# STM32H742AGI6 register map
File version: 1.0
Registers are 32-bit, access not given, reset 0x0 unless marked. A register's access mark holds for its fields unless they carry their own. Offsets are from the block's base; [hi:lo] are bit positions; {n}, {i} and the like mark numbered series; 'fields as' and 'values as' point back to an identical list.

## DMA2D
Base 0x52001000
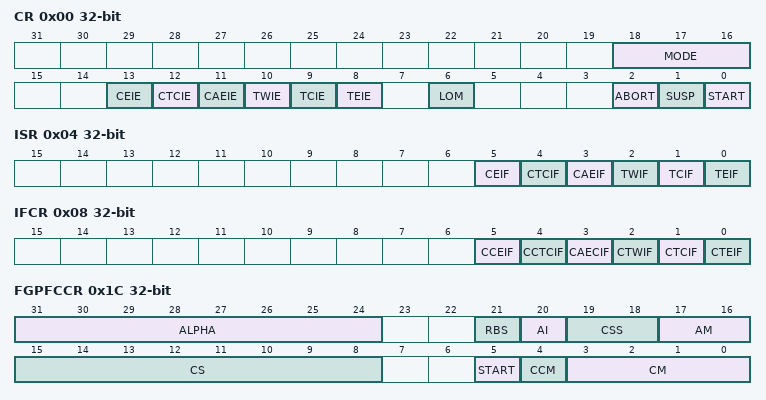
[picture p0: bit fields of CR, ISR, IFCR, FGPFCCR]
0x00 CR
  [18:16] MODE, [13] CEIE, [12] CTCIE, [11] CAEIE, [10] TWIE, [9] TCIE, [8] TEIE, [6] LOM, [2] ABORT, [1] SUSP, [0] START
0x04 ISR
  [5] CEIF, [4] CTCIF, [3] CAEIF, [2] TWIF, [1] TCIF, [0] TEIF
0x08 IFCR
  [5] CCEIF, [4] CCTCIF, [3] CAECIF, [2] CTWIF, [1] CTCIF, [0] CTEIF
0x0C FGMAR
  [31:0] MA
0x10 FGOR
  [15:0] LO
0x14 BGMAR
  [31:0] MA
0x18 BGOR
  [15:0] LO
0x1C FGPFCCR
  [31:24] ALPHA, [21] RBS, [20] AI, [19:18] CSS, [17:16] AM, [15:8] CS, [5] START, [4] CCM, [3:0] CM
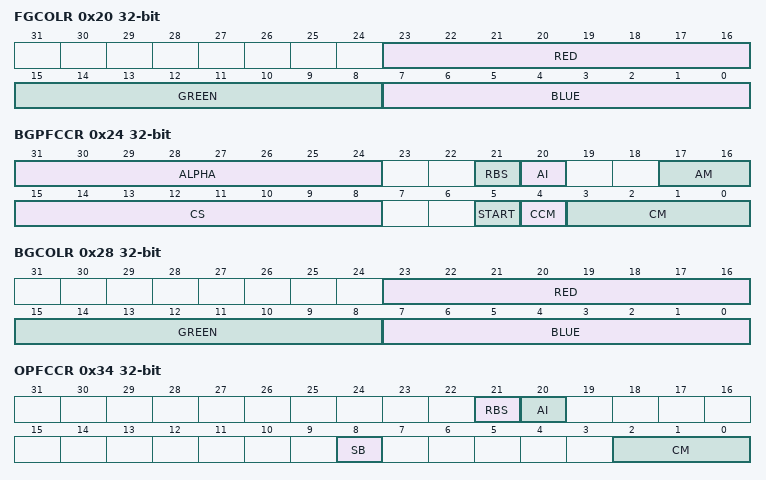
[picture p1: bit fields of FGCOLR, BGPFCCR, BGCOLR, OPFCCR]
0x20 FGCOLR
  [23:16] RED, [15:8] GREEN, [7:0] BLUE
0x24 BGPFCCR
  [31:24] ALPHA, [21] RBS, [20] AI, [17:16] AM, [15:8] CS, [5] START, [4] CCM, [3:0] CM
0x28 BGCOLR
  [23:16] RED, [15:8] GREEN, [7:0] BLUE
0x2C FGCMAR
  [31:0] MA
0x30 BGCMAR
  [31:0] MA
0x34 OPFCCR
  [21] RBS, [20] AI, [8] SB, [2:0] CM
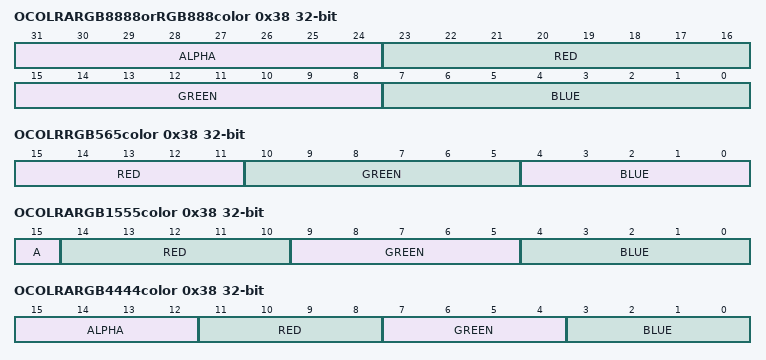
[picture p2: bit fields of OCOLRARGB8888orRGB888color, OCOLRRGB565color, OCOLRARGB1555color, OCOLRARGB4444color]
0x38 OCOLRARGB8888orRGB888color
  [31:24] ALPHA, [23:16] RED, [15:8] GREEN, [7:0] BLUE
0x38 OCOLRRGB565color
  [15:11] RED, [10:5] GREEN, [4:0] BLUE
0x38 OCOLRARGB1555color
  [15] A, [14:10] RED, [9:5] GREEN, [4:0] BLUE
0x38 OCOLRARGB4444color
  [15:12] ALPHA, [11:8] RED, [7:4] GREEN, [3:0] BLUE
0x3C OMAR
  [31:0] MA
0x40 OOR
  [15:0] LO
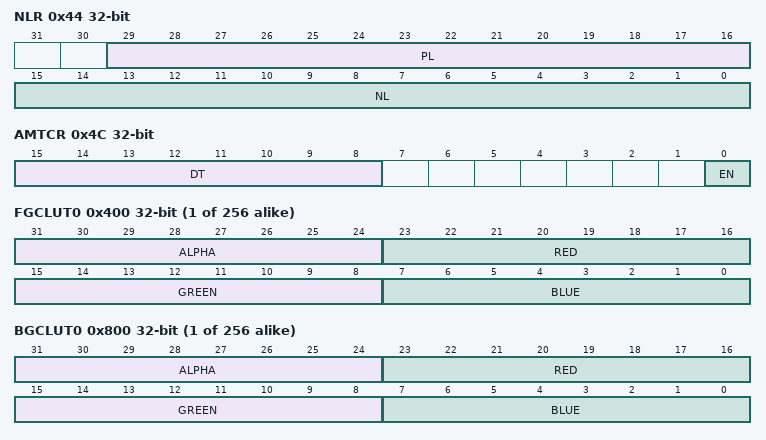
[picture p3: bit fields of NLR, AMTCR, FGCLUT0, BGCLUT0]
0x44 NLR
  [29:16] PL, [15:0] NL
0x48 LWR
  [15:0] LW
0x4C AMTCR
  [15:8] DT, [0] EN
{0x400+4i} FGCLUT{i} (i=0..255)
  [31:24] ALPHA, [23:16] RED, [15:8] GREEN, [7:0] BLUE
{0x800+4i} BGCLUT{i} (i=0..255)
  [31:24] ALPHA, [23:16] RED, [15:8] GREEN, [7:0] BLUE

## FLASH
Base 0x52002000
0x04 KEYR1
  [31:0] KEY1R
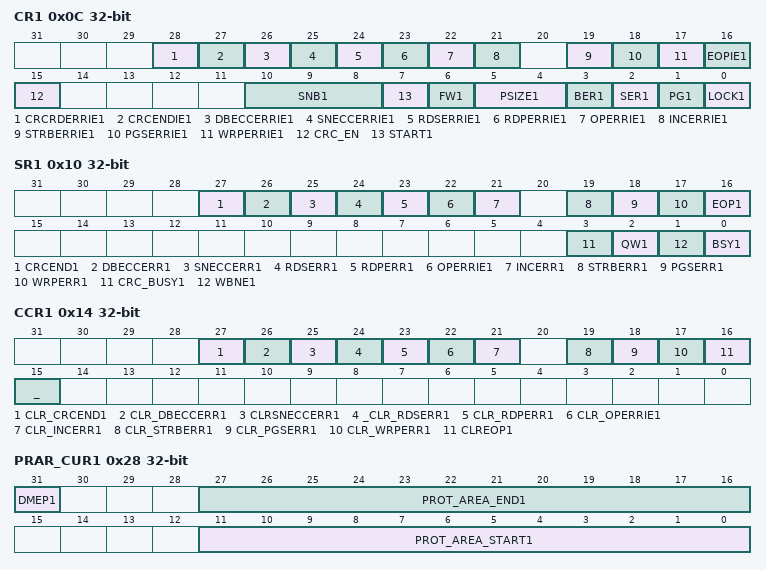
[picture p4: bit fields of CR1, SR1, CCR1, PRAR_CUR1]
0x0C CR1
  [28] CRCRDERRIE1, [27] CRCENDIE1, [26] DBECCERRIE1, [25] SNECCERRIE1, [24] RDSERRIE1, [23] RDPERRIE1, [22] OPERRIE1, [21] INCERRIE1, [19] STRBERRIE1, [18] PGSERRIE1, [17] WRPERRIE1, [16] EOPIE1, [15] CRC_EN, [10:8] SNB1, [7] START1, [6] FW1, [5:4] PSIZE1, [3] BER1, [2] SER1, [1] PG1, [0] LOCK1
0x10 SR1
  [27] CRCEND1, [26] DBECCERR1, [25] SNECCERR1, [24] RDSERR1, [23] RDPERR1, [22] OPERRIE1, [21] INCERR1, [19] STRBERR1, [18] PGSERR1, [17] WRPERR1, [16] EOP1, [3] CRC_BUSY1, [2] QW1, [1] WBNE1, [0] BSY1
0x14 CCR1
  [27] CLR_CRCEND1, [26] CLR_DBECCERR1, [25] CLRSNECCERR1, [24] _CLR_RDSERR1, [23] CLR_RDPERR1, [22] CLR_OPERRIE1, [21] CLR_INCERR1, [19] CLR_STRBERR1, [18] CLR_PGSERR1, [17] CLR_WRPERR1, [16] CLREOP1, [15] _
0x28 PRAR_CUR1
  [31] DMEP1, [27:16] PROT_AREA_END1, [11:0] PROT_AREA_START1
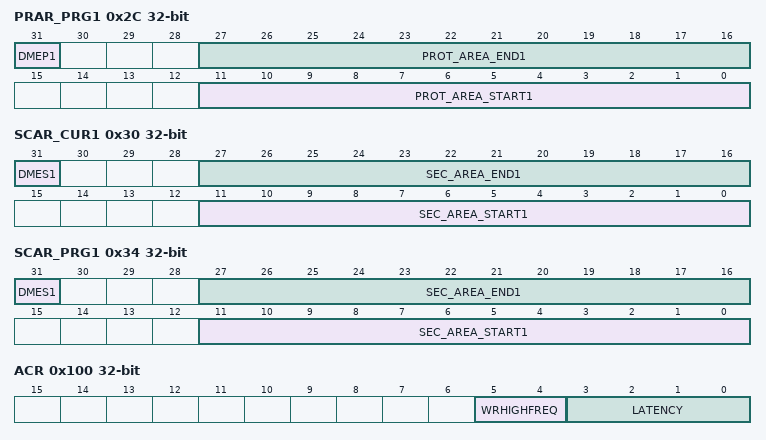
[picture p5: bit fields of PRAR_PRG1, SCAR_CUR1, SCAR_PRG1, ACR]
0x2C PRAR_PRG1
  [31] DMEP1, [27:16] PROT_AREA_END1, [11:0] PROT_AREA_START1
0x30 SCAR_CUR1
  [31] DMES1, [27:16] SEC_AREA_END1, [11:0] SEC_AREA_START1
0x34 SCAR_PRG1
  [31] DMES1, [27:16] SEC_AREA_END1, [11:0] SEC_AREA_START1
0x38 WPSN_CUR1R
  [7:0] WRPSn1
0x3C WPSN_PRG1R
  [7:0] WRPSn1
0x50 CRCCR1
  [21:20] CRC_BURST, [17] CLEAN_CRC, [16] STARTCRC, [10] CLEAN_SECT, [9] ADD_SECT, [8] CRC_BY_SECT, [7] ALLBANK, [15:6] _, [2:0] CRC_SECT
0x54 CRCSADD1R
  [19:2] CRC_START_ADDR
0x58 CRCEADD1R
  [19:2] CRC_END_ADDR
0x60 ECC_FA1R
  [14:0] FAIL_ECC_ADDR1
0x100 ACR
  [5:4] WRHIGHFREQ, [3:0] LATENCY
0x104 KEYR2
  [31:0] KEY2R
0x108 OPTKEYR
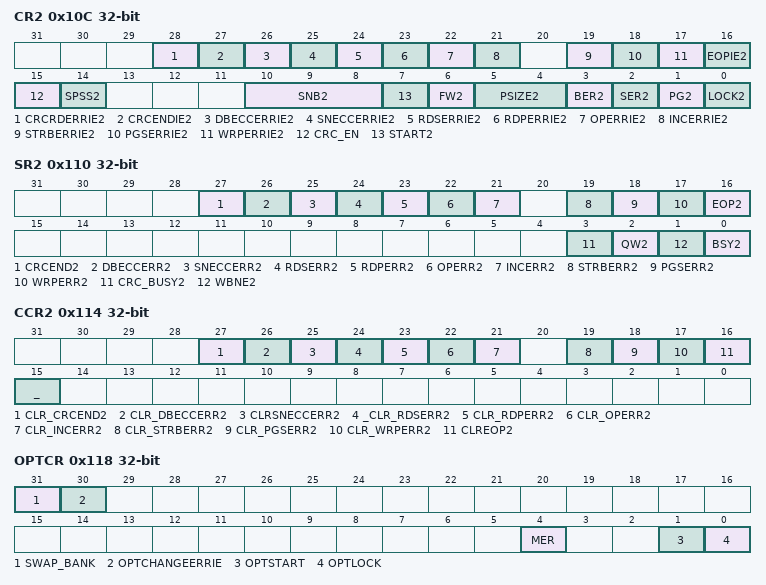
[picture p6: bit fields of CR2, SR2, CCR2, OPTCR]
0x10C CR2
  [28] CRCRDERRIE2, [27] CRCENDIE2, [26] DBECCERRIE2, [25] SNECCERRIE2, [24] RDSERRIE2, [23] RDPERRIE2, [22] OPERRIE2, [21] INCERRIE2, [19] STRBERRIE2, [18] PGSERRIE2, [17] WRPERRIE2, [16] EOPIE2, [15] CRC_EN, [14] SPSS2, [10:8] SNB2, [7] START2, [6] FW2, [5:4] PSIZE2, [3] BER2, [2] SER2, [1] PG2, [0] LOCK2
0x110 SR2
  [27] CRCEND2, [26] DBECCERR2, [25] SNECCERR2, [24] RDSERR2, [23] RDPERR2, [22] OPERR2, [21] INCERR2, [19] STRBERR2, [18] PGSERR2, [17] WRPERR2, [16] EOP2, [3] CRC_BUSY2, [2] QW2, [1] WBNE2, [0] BSY2
0x114 CCR2
  [27] CLR_CRCEND2, [26] CLR_DBECCERR2, [25] CLRSNECCERR2, [24] _CLR_RDSERR2, [23] CLR_RDPERR2, [22] CLR_OPERR2, [21] CLR_INCERR2, [19] CLR_STRBERR2, [18] CLR_PGSERR2, [17] CLR_WRPERR2, [16] CLREOP2, [15] _
0x118 OPTCR
  [31] SWAP_BANK, [30] OPTCHANGEERRIE, [4] MER, [1] OPTSTART, [0] OPTLOCK
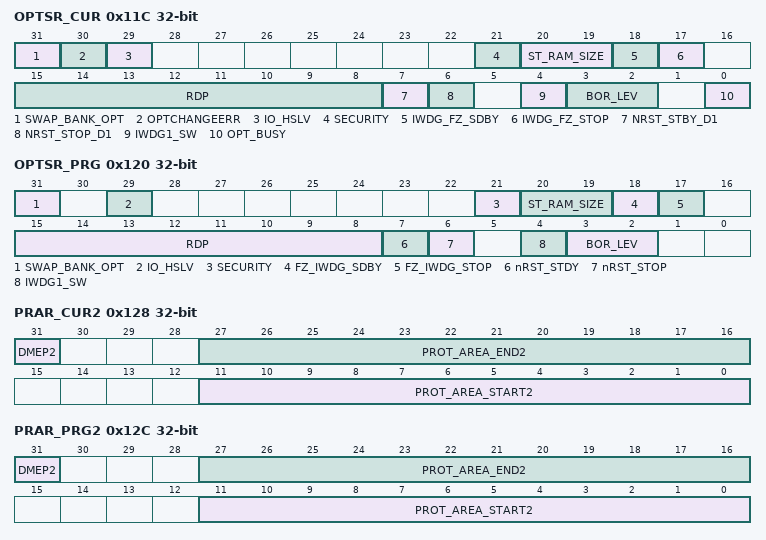
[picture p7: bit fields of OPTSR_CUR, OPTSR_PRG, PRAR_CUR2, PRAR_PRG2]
0x11C OPTSR_CUR
  [31] SWAP_BANK_OPT, [30] OPTCHANGEERR, [29] IO_HSLV, [21] SECURITY, [20:19] ST_RAM_SIZE, [18] IWDG_FZ_SDBY, [17] IWDG_FZ_STOP, [15:8] RDP, [7] NRST_STBY_D1, [6] NRST_STOP_D1, [4] IWDG1_SW, [3:2] BOR_LEV, [0] OPT_BUSY
0x120 OPTSR_PRG
  [31] SWAP_BANK_OPT, [29] IO_HSLV, [21] SECURITY, [20:19] ST_RAM_SIZE, [18] FZ_IWDG_SDBY, [17] FZ_IWDG_STOP, [15:8] RDP, [7] nRST_STDY, [6] nRST_STOP, [4] IWDG1_SW, [3:2] BOR_LEV
0x124 OPTCCR
  [30] CLR_OPTCHANGEERR
0x128 PRAR_CUR2
  [31] DMEP2, [27:16] PROT_AREA_END2, [11:0] PROT_AREA_START2
0x12C PRAR_PRG2
  [31] DMEP2, [27:16] PROT_AREA_END2, [11:0] PROT_AREA_START2
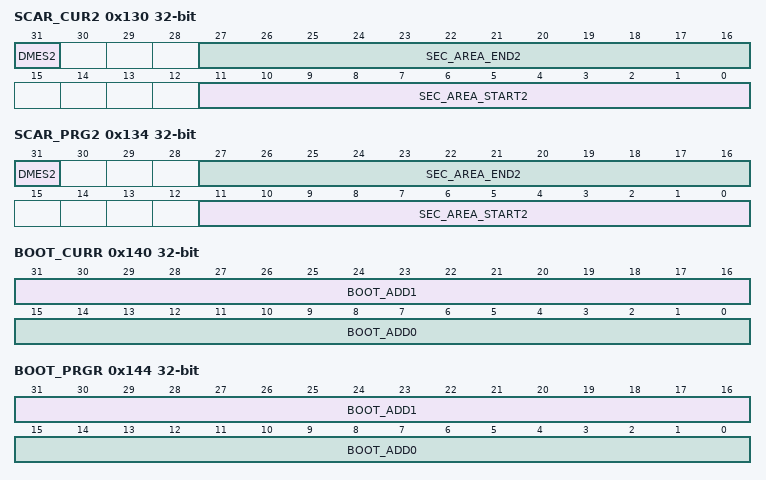
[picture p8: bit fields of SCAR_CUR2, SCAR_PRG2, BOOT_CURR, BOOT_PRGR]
0x130 SCAR_CUR2
  [31] DMES2, [27:16] SEC_AREA_END2, [11:0] SEC_AREA_START2
0x134 SCAR_PRG2
  [31] DMES2, [27:16] SEC_AREA_END2, [11:0] SEC_AREA_START2
0x138 WPSN_CUR2R
  [7:0] WRPSn2
0x13C WPSN_PRG2R
  [7:0] WRPSn2
0x140 BOOT_CURR
  [31:16] BOOT_ADD1, [15:0] BOOT_ADD0
0x144 BOOT_PRGR
  [31:16] BOOT_ADD1, [15:0] BOOT_ADD0
0x150 CRCCR2
  fields as CRCCR1
0x154 CRCSADD2R
  [19:2] CRC_START_ADDR
0x158 CRCEADD2R
  [19:2] CRC_END_ADDR
0x15C CRCDATAR
  [31:0] CRC_DATA
0x160 ECC_FA2R
  [15:0] FAIL_ECC_ADDR2
